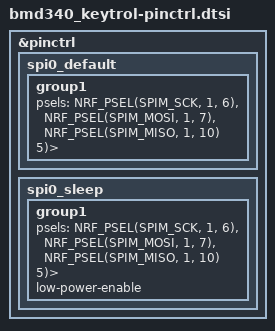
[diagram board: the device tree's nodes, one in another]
/*
 * Copyright (c) 2022 The ZMK Contributors
 * SPDX-License-Identifier: MIT
 */

&pinctrl {

    spi0_default: spi0_default {
        group1 {
            psels = <NRF_PSEL(SPIM_SCK, 1, 6)>,
                <NRF_PSEL(SPIM_MOSI, 1, 7)>,
                <NRF_PSEL(SPIM_MISO, 1, 10)>;
                <NRF_PSEL(SPIM_CS, 1, 5)>;
        };
    };

    spi0_sleep: spi0_sleep {
        group1 {
            psels = <NRF_PSEL(SPIM_SCK, 1, 6)>,
                <NRF_PSEL(SPIM_MOSI, 1, 7)>,
                <NRF_PSEL(SPIM_MISO, 1, 10)>;
                <NRF_PSEL(SPIM_CS, 1, 5)>;
            low-power-enable;
        };
    };
};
